# AT90USB1286 register map
Vendor: Atmel; File version: 1.0
CPU: other r0p0, little endian, no MPU, no FPU, 4 interrupt priority bits
Registers are 8-bit, read-write, reset 0x0 unless marked. A register's access mark holds for its fields unless they carry their own. Offsets are from the block's base; [hi:lo] are bit positions; {n}, {i} and the like mark numbered series; 'fields as' and 'values as' point back to an identical list.

## ADC — Analog-to-Digital Converter
Base 0x00000078
0x00 ADC 16-bit (reset mask 0xFF) — ADC Data Register Bytes
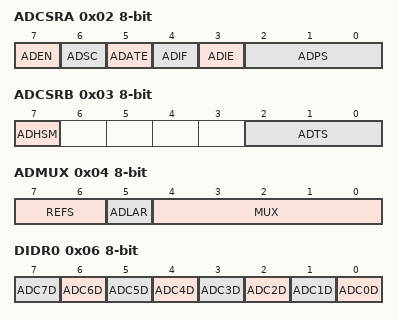
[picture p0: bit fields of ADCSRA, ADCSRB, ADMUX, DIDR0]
0x02 ADCSRA — The ADC Control and Status register
  [7] ADEN — ADC Enable
  [6] ADSC — ADC Start Conversion
  [5] ADATE — ADC Auto Trigger Enable
  [4] ADIF — ADC Interrupt Flag
  [3] ADIE — ADC Interrupt Enable
  [2:0] ADPS — ADC Prescaler Select Bits
    0=2; 1=2; 2=4; 3=8; 4=16; 5=32; 6=64; 7=128
0x03 ADCSRB — ADC Control and Status Register B
  [7] ADHSM — ADC High Speed Mode
  [2:0] ADTS — ADC Auto Trigger Sources
    0=Free Running mode; 1=Analog Comparator; 2=External Interrupt Request 0; 3=Timer/Counter0 Compare Match A; 4=Timer/Counter0 Overflow; 5=Timer/Counter1 Compare Match B; 6=Timer/Counter1 Overflow; 7=Timer/Counter1 Capture Event
0x04 ADMUX — The ADC multiplexer Selection Register
  [7:6] REFS — Reference Selection Bits
    0=AREF, Internal Vref turned off; 1=AVCC with external capacitor at AREF pin; 3=Internal 2.56V Voltage Reference with external capacitor at AREF pin
  [5] ADLAR — Left Adjust Result
  [4:0] MUX — Analog Channel and Gain Selection Bits
0x06 DIDR0 — Digital Input Disable Register 1
  [n] ADC{n}D (n=0..7) — ADC{n} Digital input Disable

## BOOT_LOAD — Bootloader
Base 0x00000057
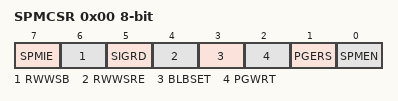
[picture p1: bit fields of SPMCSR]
0x00 SPMCSR — Store Program Memory Control Register
  [7] SPMIE — SPM Interrupt Enable
  [6] RWWSB — Read While Write Section Busy
  [5] SIGRD — Signature Row Read
  [4] RWWSRE — Read While Write section read enable
  [3] BLBSET — Boot Lock Bit Set
  [2] PGWRT — Page Write
  [1] PGERS — Page Erase
  [0] SPMEN — Store Program Memory Enable

## CPU — CPU Registers
Base 0x0000003E
0x00 GPIOR0 — General Purpose IO Register 0
0x0C GPIOR1 — General Purpose IO Register 1
0x0D GPIOR2 — General Purpose IO Register 2
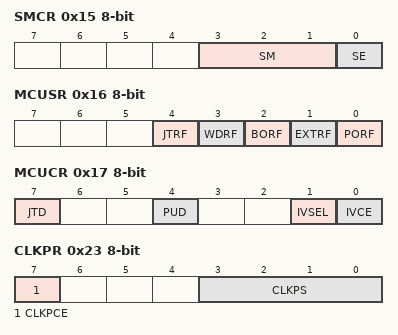
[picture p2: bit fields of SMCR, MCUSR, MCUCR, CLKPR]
0x15 SMCR — Sleep Mode Control Register
  [3:1] SM — Sleep Mode Select bits
    0=IDLE; 1=ADC (ADC Noise Reduction (If Available)); 2=PDOWN (Power Down); 3=PSAVE (Power Save); 6=STDBY (Standby); 7=ESTDBY (Extended Standby)
  [0] SE — Sleep Enable
0x16 MCUSR — MCU Status Register
  [4] JTRF — JTAG Reset Flag
  [3] WDRF — Watchdog Reset Flag
  [2] BORF — Brown-out Reset Flag
  [1] EXTRF — External Reset Flag
  [0] PORF — Power-on reset flag
0x17 MCUCR — MCU Control Register
  [7] JTD — JTAG Interface Disable
  [4] PUD — Pull-up disable
  [1] IVSEL — Interrupt Vector Select
  [0] IVCE — Interrupt Vector Change Enable
0x1D RAMPZ — RAM Page Z Select Register
0x1E EIND — Extended Indirect Register
0x23 CLKPR
  [7] CLKPCE
  [3:0] CLKPS
    0=1; 1=2; 2=4; 3=8; 4=16; 5=32; 6=64; 7=128; 8=256
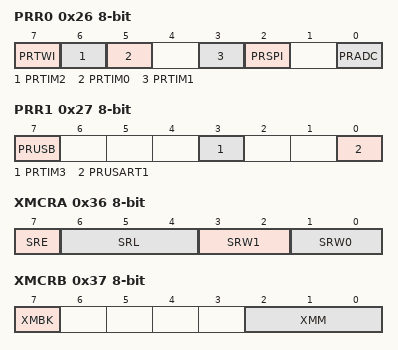
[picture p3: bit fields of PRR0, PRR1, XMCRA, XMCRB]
0x26 PRR0 — Power Reduction Register0
  [7] PRTWI — Power Reduction TWI
  [6] PRTIM2 — Power Reduction Timer/Counter2
  [5] PRTIM0 — Power Reduction Timer/Counter0
  [3] PRTIM1 — Power Reduction Timer/Counter1
  [2] PRSPI — Power Reduction Serial Peripheral Interface
  [0] PRADC — Power Reduction ADC
0x27 PRR1 — Power Reduction Register1
  [7] PRUSB — Power Reduction USB
  [3] PRTIM3 — Power Reduction Timer/Counter3
  [0] PRUSART1 — Power Reduction USART1
0x28 OSCCAL — Oscillator Calibration Value
  [7:0] OSCCAL — Oscillator Calibration
0x36 XMCRA — External Memory Control Register A
  [7] SRE — External SRAM Enable
  [6:4] SRL — Wait state page limit
    0=LS = N/A, US = 0x1100 - 0xFFFF; 1=LS = 0x2100 - 0x1FFF, US = 0x2000 - 0xFFFF; 2=LS = 0x2100 - 0x3FFF, US = 0x4000 - 0xFFFF; 3=LS = 0x2100 - 0x5FFF, US = 0x6000 - 0xFFFF; 4=LS = 0x2100 - 0x7FFF, US = 0x8000 - 0xFFFF; 5=LS = 0x2100 - 0x9FFF, US = 0xA000 - 0xFFFF; 6=LS = 0x2100 - 0xBFFF, US = 0xC000 - 0xFFFF; 7=LS = 0x2100 - 0xDFFF, US = 0xE000 - 0xFFFF
  [3:2] SRW1 — Wait state select bit upper page
    0=No wait-states; 1=Wait one cycle during read/write strobe; 2=Wait two cycles during read/write strobe; 3=Wait two cycles during read/write and wait one cycle before driving out new address
  [1:0] SRW0 — Wait state select bit lower page
    values as SRW1
0x37 XMCRB — External Memory Control Register B
  [7] XMBK — External Memory Bus Keeper Enable
  [2:0] XMM — External Memory High Mask
    0=None; 1=Px7; 2=Px7-Px6; 3=Px7-Px5; 4=Px7-Px4; 5=Px7-Px3; 6=Px7-Px2; 7=Full Port X
